# iospear600 register map
Registers are 32-bit, access not given, no defined reset value unless marked. A register's access mark holds for its fields unless they carry their own. Addresses are absolute; registers are grouped by the start of their names; [hi:lo] are bit positions; {n}, {i} and the like mark numbered series; 'fields as' and 'values as' point back to an identical list.

## GMAC
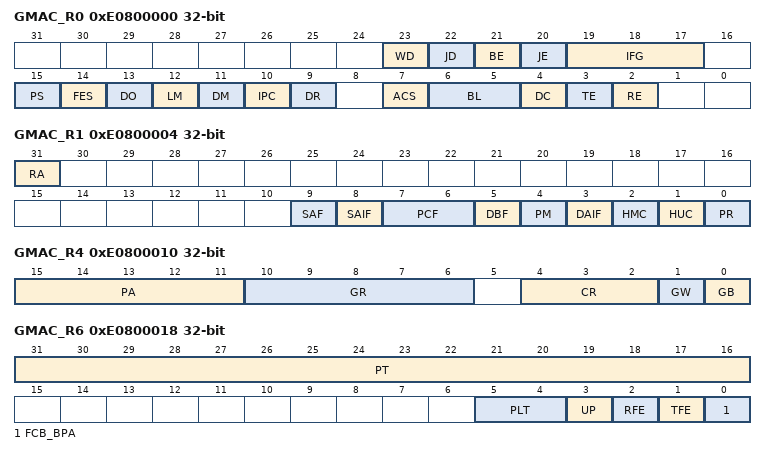
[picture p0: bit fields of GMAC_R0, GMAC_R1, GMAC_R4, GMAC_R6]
0xE0800000 GMAC_R0
  [23] WD, [22] JD, [21] BE, [20] JE, [19:17] IFG, [15] PS, [14] FES, [13] DO, [12] LM, [11] DM, [10] IPC, [9] DR, [7] ACS, [6:5] BL, [4] DC, [3] TE, [2] RE
0xE0800004 GMAC_R1
  [31] RA, [9] SAF, [8] SAIF, [7:6] PCF, [5] DBF, [4] PM, [3] DAIF, [2] HMC, [1] HUC, [0] PR
0xE0800008 GMAC_R2
0xE080000C GMAC_R3
0xE0800010 GMAC_R4
  [15:11] PA, [10:6] GR, [4:2] CR, [1] GW, [0] GB
0xE0800014 GMAC_R5
  [15:0] GD
0xE0800018 GMAC_R6
  [31:16] PT, [5:4] PLT, [3] UP, [2] RFE, [1] TFE, [0] FCB_BPA
0xE080001C GMAC_R7
  [15:0] VL
0xE0800020 GMAC_R8
0xE0800028 GMAC_R10
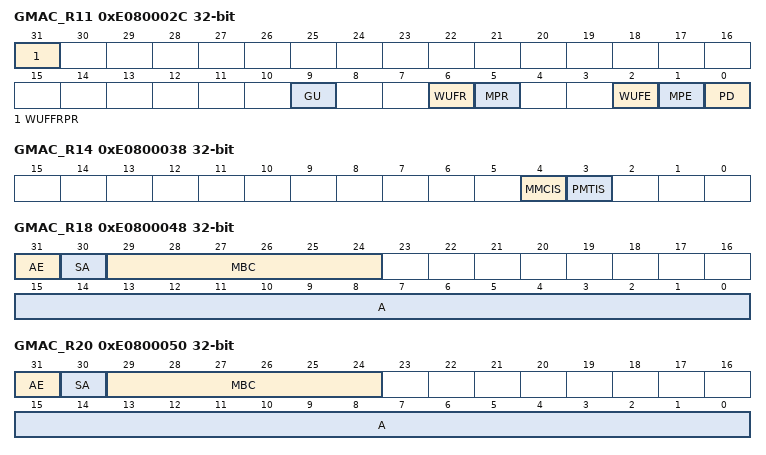
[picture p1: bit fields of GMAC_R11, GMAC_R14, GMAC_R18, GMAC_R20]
0xE080002C GMAC_R11
  [31] WUFFRPR, [9] GU, [6] WUFR, [5] MPR, [2] WUFE, [1] MPE, [0] PD
0xE0800030 GMAC_R16 16-bit
0xE0800034 GMAC_R17
0xE0800038 GMAC_R14
  [4] MMCIS, [3] PMTIS
0xE080003C GMAC_R15
  [3] PMTIN
0xE0800048 GMAC_R18
  [31] AE, [30] SA, [29:24] MBC, [15:0] A
0xE080004C GMAC_R19
0xE0800050 GMAC_R20
  [31] AE, [30] SA, [29:24] MBC, [15:0] A
0xE0800054 GMAC_R21
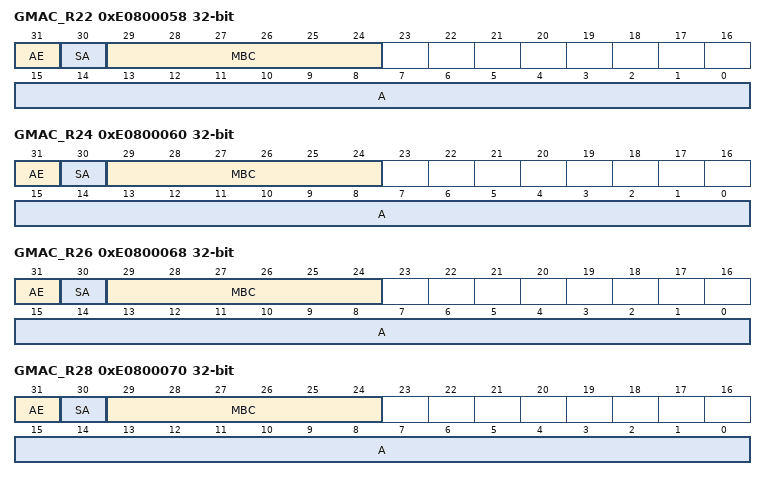
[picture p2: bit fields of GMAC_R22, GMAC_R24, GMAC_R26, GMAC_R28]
0xE0800058 GMAC_R22
  [31] AE, [30] SA, [29:24] MBC, [15:0] A
0xE080005C GMAC_R23
0xE0800060 GMAC_R24
  [31] AE, [30] SA, [29:24] MBC, [15:0] A
0xE0800064 GMAC_R25
0xE0800068 GMAC_R26
  [31] AE, [30] SA, [29:24] MBC, [15:0] A
0xE080006C GMAC_R27
0xE0800070 GMAC_R28
  [31] AE, [30] SA, [29:24] MBC, [15:0] A
0xE0800074 GMAC_R29
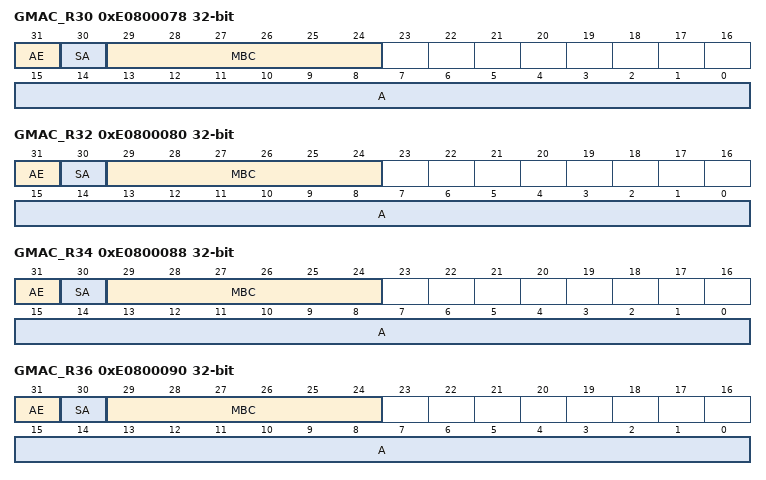
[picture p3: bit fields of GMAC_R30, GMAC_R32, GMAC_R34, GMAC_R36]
0xE0800078 GMAC_R30
  [31] AE, [30] SA, [29:24] MBC, [15:0] A
0xE080007C GMAC_R31
0xE0800080 GMAC_R32
  [31] AE, [30] SA, [29:24] MBC, [15:0] A
0xE0800084 GMAC_R33
0xE0800088 GMAC_R34
  [31] AE, [30] SA, [29:24] MBC, [15:0] A
0xE080008C GMAC_R35
0xE0800090 GMAC_R36
  [31] AE, [30] SA, [29:24] MBC, [15:0] A
0xE0800094 GMAC_R37
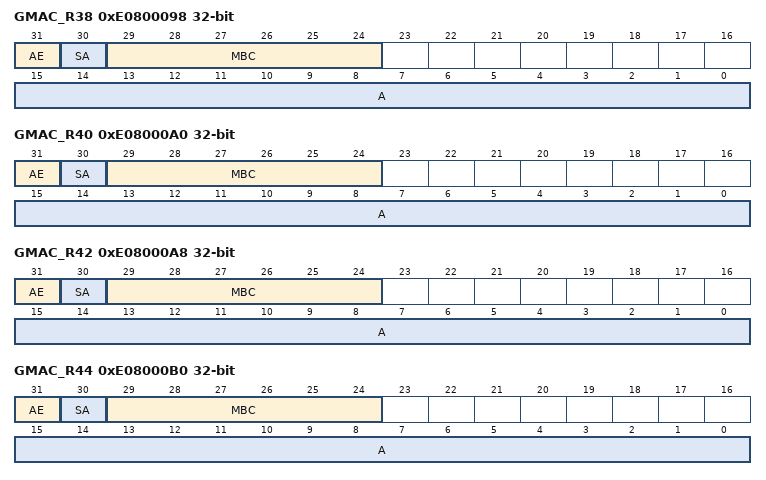
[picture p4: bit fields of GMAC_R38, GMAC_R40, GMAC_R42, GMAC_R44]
0xE0800098 GMAC_R38
  [31] AE, [30] SA, [29:24] MBC, [15:0] A
0xE080009C GMAC_R39
0xE08000A0 GMAC_R40
  [31] AE, [30] SA, [29:24] MBC, [15:0] A
0xE08000A4 GMAC_R41
0xE08000A8 GMAC_R42
  [31] AE, [30] SA, [29:24] MBC, [15:0] A
0xE08000AC GMAC_R43
0xE08000B0 GMAC_R44
  [31] AE, [30] SA, [29:24] MBC, [15:0] A
0xE08000B4 GMAC_R45
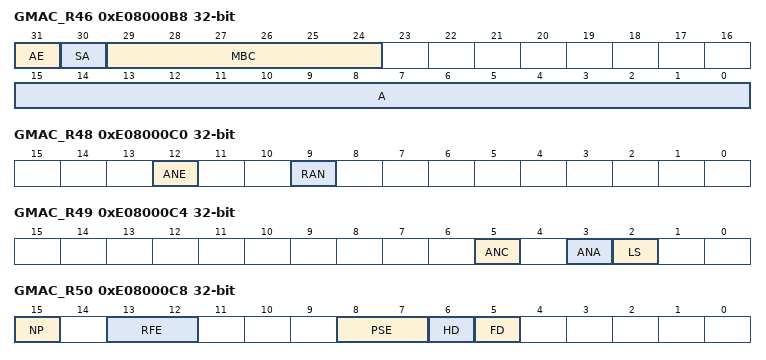
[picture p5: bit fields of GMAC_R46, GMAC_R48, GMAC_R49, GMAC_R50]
0xE08000B8 GMAC_R46
  [31] AE, [30] SA, [29:24] MBC, [15:0] A
0xE08000BC GMAC_R47
0xE08000C0 GMAC_R48
  [12] ANE, [9] RAN
0xE08000C4 GMAC_R49
  [5] ANC, [3] ANA, [2] LS
0xE08000C8 GMAC_R50
  [15] NP, [13:12] RFE, [8:7] PSE, [6] HD, [5] FD
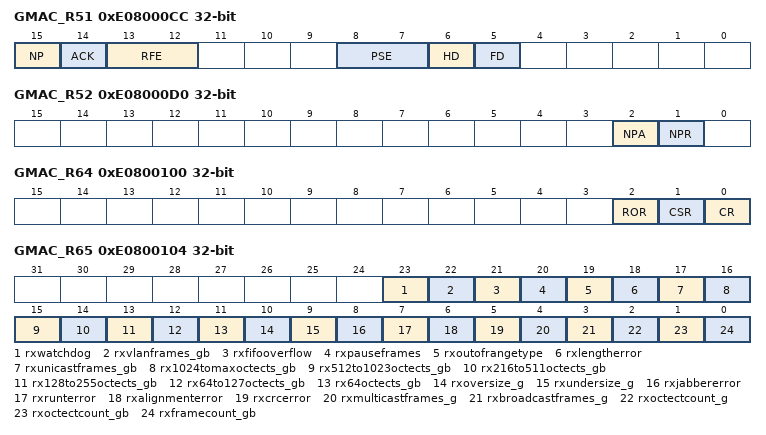
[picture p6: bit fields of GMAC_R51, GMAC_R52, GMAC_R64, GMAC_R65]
0xE08000CC GMAC_R51
  [15] NP, [14] ACK, [13:12] RFE, [8:7] PSE, [6] HD, [5] FD
0xE08000D0 GMAC_R52
  [2] NPA, [1] NPR
0xE0800100 GMAC_R64
  [2] ROR, [1] CSR, [0] CR
0xE0800104 GMAC_R65
  [23] rxwatchdog, [22] rxvlanframes_gb, [21] rxfifooverflow, [20] rxpauseframes, [19] rxoutofrangetype, [18] rxlengtherror, [17] rxunicastframes_gb, [16] rx1024tomaxoctects_gb, [15] rx512to1023octects_gb, [14] rx216to511octects_gb, [13] rx128to255octects_gb, [12] rx64to127octects_gb, [11] rx64octects_gb, [10] rxoversize_g, [9] rxundersize_g, [8] rxjabbererror, [7] rxrunterror, [6] rxalignmenterror, [5] rxcrcerror, [4] rxmulticastframes_g, [3] rxbroadcastframes_g, [2] rxoctectcount_g, [1] rxoctectcount_gb, [0] rxframecount_gb
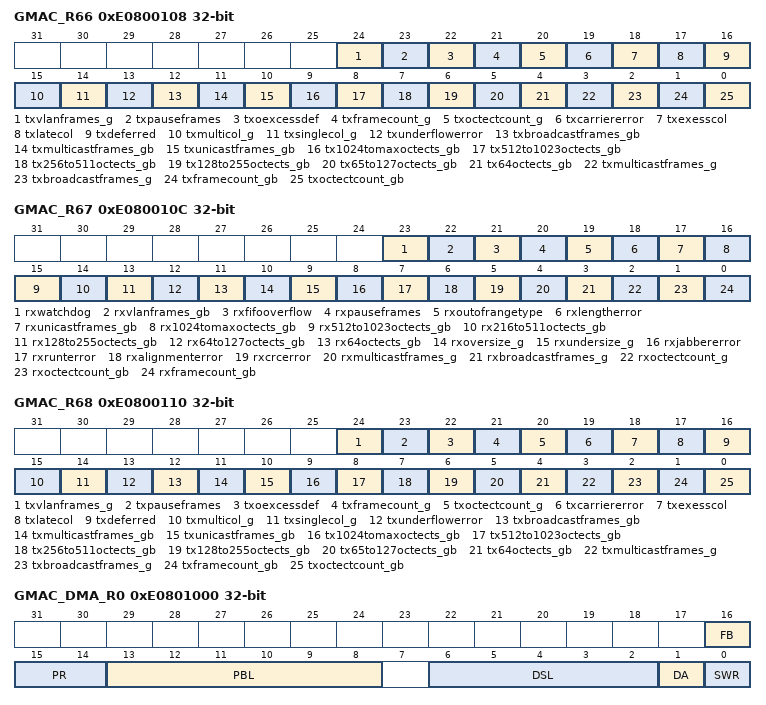
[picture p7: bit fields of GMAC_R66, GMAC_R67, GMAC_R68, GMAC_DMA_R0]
0xE0800108 GMAC_R66
  [24] txvlanframes_g, [23] txpauseframes, [22] txoexcessdef, [21] txframecount_g, [20] txoctectcount_g, [19] txcarriererror, [18] txexesscol, [17] txlatecol, [16] txdeferred, [15] txmulticol_g, [14] txsinglecol_g, [13] txunderflowerror, [12] txbroadcastframes_gb, [11] txmulticastframes_gb, [10] txunicastframes_gb, [9] tx1024tomaxoctects_gb, [8] tx512to1023octects_gb, [7] tx256to511octects_gb, [6] tx128to255octects_gb, [5] tx65to127octects_gb, [4] tx64octects_gb, [3] txmulticastframes_g, [2] txbroadcastframes_g, [1] txframecount_gb, [0] txoctectcount_gb
0xE080010C GMAC_R67
  fields as GMAC_R65
0xE0800110 GMAC_R68
  fields as GMAC_R66
{0xE0800000+4i} GMAC_R{i} (i=69..93)
{0xE0800000+4i} GMAC_R{i} (i=96..119)
0xE0801000 GMAC_DMA_R0
  [16] FB, [15:14] PR, [13:8] PBL, [6:2] DSL, [1] DA, [0] SWR
{0xE0801000+4i} GMAC_DMA_R{i} (i=1..4)
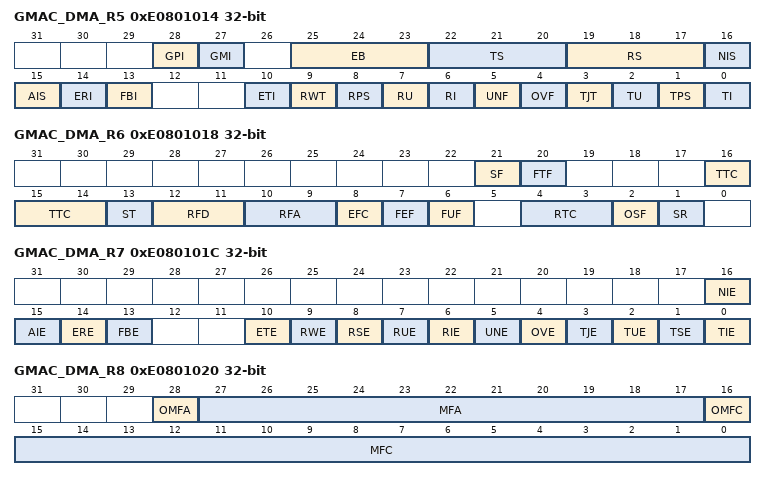
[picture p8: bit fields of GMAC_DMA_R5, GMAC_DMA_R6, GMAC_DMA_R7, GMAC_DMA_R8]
0xE0801014 GMAC_DMA_R5
  [28] GPI, [27] GMI, [25:23] EB, [22:20] TS, [19:17] RS, [16] NIS, [15] AIS, [14] ERI, [13] FBI, [10] ETI, [9] RWT, [8] RPS, [7] RU, [6] RI, [5] UNF, [4] OVF, [3] TJT, [2] TU, [1] TPS, [0] TI
0xE0801018 GMAC_DMA_R6
  [21] SF, [20] FTF, [16:14] TTC, [13] ST, [12:11] RFD, [10:9] RFA, [8] EFC, [7] FEF, [6] FUF, [4:3] RTC, [2] OSF, [1] SR
0xE080101C GMAC_DMA_R7
  [16] NIE, [15] AIE, [14] ERE, [13] FBE, [10] ETE, [9] RWE, [8] RSE, [7] RUE, [6] RIE, [5] UNE, [4] OVE, [3] TJE, [2] TUE, [1] TSE, [0] TIE
0xE0801020 GMAC_DMA_R8
  [28] OMFA, [27:17] MFA, [16] OMFC, [15:0] MFC
{0xE0801000+4i} GMAC_DMA_R{i} (i=18..21)
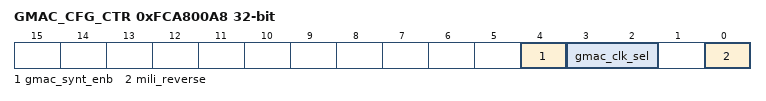
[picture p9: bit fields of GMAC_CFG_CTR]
0xFCA800A8 GMAC_CFG_CTR
  [4] gmac_synt_enb, [3:2] gmac_clk_sel, [0] mili_reverse
